 BO_ 213 BRAKE_POSITION: 8 XXX
 SG_ BRAKE_POSITION : 0|9@1+ (1,0) [0|1] "" XXX

BO_ 287 STEER_ANGLE_SENSOR: 5 XXX
 SG_ STEER_RACK_ANGLE : 0|16@1- (0.01,0) [-50|50] "deg" XXX
 SG_ STEER_TORQUE_MAG : 16|8@1+ (1,0) [0|255] "Nm" XXX

BO_ 289 NEW_MSG_121: 8 XXX

BO_ 482 NEW_MSG_1E2: 8 XXX
 SG_ STEER_ANGLE_2 : 24|16@1- (0.01,0) [0|65535] "" XXX

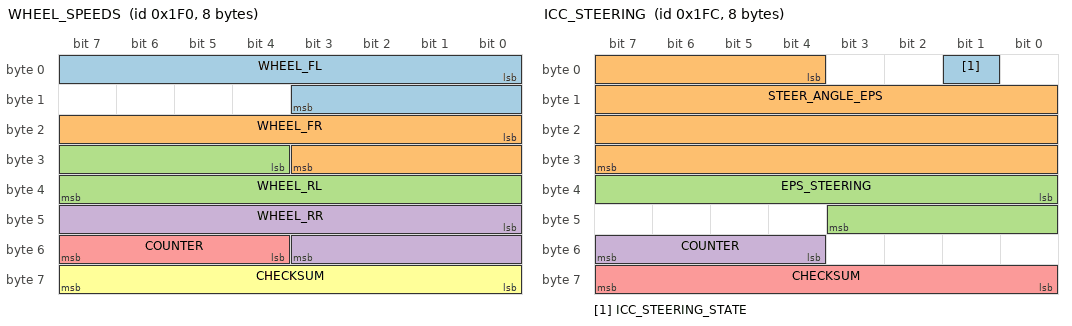
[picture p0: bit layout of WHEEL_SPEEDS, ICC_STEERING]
BO_ 496 WHEEL_SPEEDS: 8 XXX
 SG_ WHEEL_FL : 0|12@1+ (0.075,0) [0|4095] "" XXX
 SG_ WHEEL_FR : 16|12@1+ (0.075,0) [0|4095] "" XXX
 SG_ WHEEL_RL : 28|12@1+ (0.075,0) [0|31] "" XXX
 SG_ WHEEL_RR : 40|12@1+ (0.075,0) [0|8191] "" XXX
 SG_ COUNTER : 55|4@0+ (1,0) [0|15] "" XXX
 SG_ CHECKSUM : 56|8@1+ (1,0) [0|255] "" XXX

BO_ 508 ICC_STEERING: 8 XXX
 SG_ ICC_STEERING_STATE : 1|1@0+ (1,0) [0|1] "" XXX
 SG_ STEER_ANGLE_EPS : 4|28@1- (1,0) [-1000|1000] "" XXX
 SG_ EPS_STEERING : 32|12@1- (1,0) [-2048|2047] "" XXX
 SG_ COUNTER : 55|4@0+ (1,0) [0|15] "" XXX
 SG_ CHECKSUM : 63|8@0+ (1,0) [0|15] "" XXX

BO_ 537 BRAKE: 8 XXX
 SG_ BRAKE_PRESSED : 2|1@0+ (1,0) [0|1] "" XXX

BO_ 544 NEW_MSG_220: 8 XXX

BO_ 546 YAW_RATE: 8 XXX
 SG_ YAW_RATE : 0|11@1+ (1,-982) [0|2047] "" XXX

BO_ 547 NEW_MSG_223: 8 XXX

BO_ 578 NEW_MSG_242: 8 XXX
 SG_ GAS_PEDAL_2 : 30|7@0+ (1,0) [0|127] "" XXX
 SG_ BRAKE_STATE : 37|1@0+ (1,0) [0|1] "" XXX

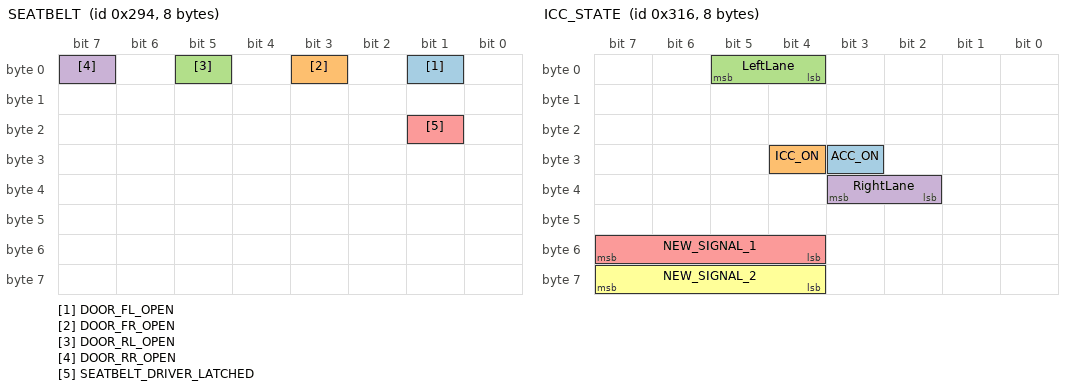
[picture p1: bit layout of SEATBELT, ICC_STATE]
BO_ 660 SEATBELT: 8 XXX
 SG_ DOOR_FL_OPEN : 1|1@0+ (1,0) [0|1] "" XXX
 SG_ DOOR_FR_OPEN : 3|1@0+ (1,0) [0|1] "" XXX
 SG_ DOOR_RL_OPEN : 5|1@0+ (1,0) [0|1] "" XXX
 SG_ DOOR_RR_OPEN : 7|1@0+ (1,0) [0|1] "" XXX
 SG_ SEATBELT_DRIVER_LATCHED : 17|1@0+ (1,0) [0|1] "" XXX

BO_ 661 NEW_MSG_295: 8 XXX

BO_ 790 ICC_STATE: 8 XXX
 SG_ ACC_ON : 27|1@0+ (1,0) [0|1] "" XXX
 SG_ ICC_ON : 28|1@0+ (1,0) [0|1] "" XXX
 SG_ LeftLane : 4|2@1+ (1,0) [0|3] "" XXX
 SG_ RightLane : 34|2@1+ (1,0) [0|3] "" XXX
 SG_ NEW_SIGNAL_1 : 55|4@0+ (1,0) [0|15] "" XXX
 SG_ NEW_SIGNAL_2 : 63|4@0+ (1,0) [0|15] "" XXX

BO_ 814 ICC_GAS_NOTSURE: 8 XXX
 SG_ GAS_NOTSURE : 7|16@0+ (1,0) [0|65535] "" XXX
 SG_ CHECKSUM : 51|12@0+ (1,0) [0|4095] "" XXX

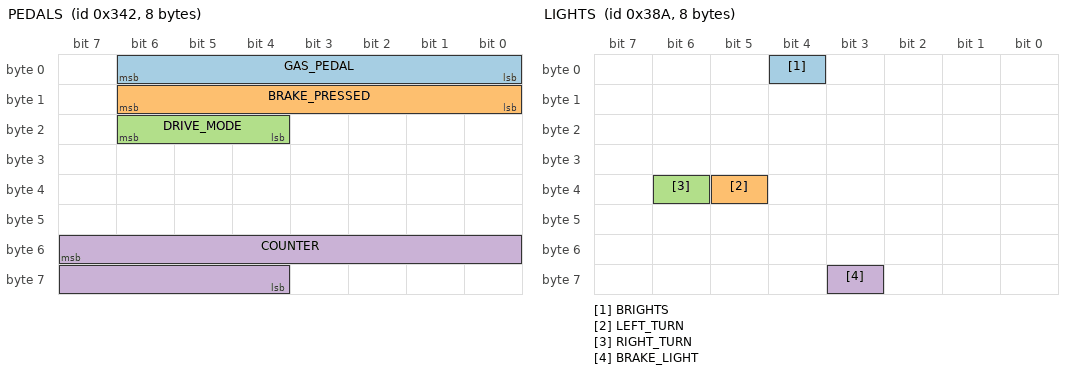
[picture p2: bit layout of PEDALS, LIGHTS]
BO_ 834 PEDALS: 8 XXX
 SG_ GAS_PEDAL : 6|7@0+ (1,0) [0|127] "" XXX
 SG_ BRAKE_PRESSED : 14|7@0+ (1,0) [0|1] "" XXX
 SG_ DRIVE_MODE : 22|3@0+ (1,0) [0|7] "" XXX
 SG_ COUNTER : 55|12@0+ (1,0) [0|4095] "" XXX

BO_ 854 NEW_MSG_356: 8 XXX

BO_ 860 GEAR_STATE: 8 XXX
 SG_ GEAR_STATE : 8|3@1+ (1,0) [0|7] "" XXX

BO_ 906 LIGHTS: 8 XXX
 SG_ BRIGHTS : 4|1@0+ (1,0) [0|1] "" XXX
 SG_ LEFT_TURN : 37|1@0+ (1,0) [0|1] "" XXX
 SG_ RIGHT_TURN : 38|1@0+ (1,0) [0|1] "" XXX
 SG_ BRAKE_LIGHT : 59|1@0+ (1,0) [0|1] "" XXX

BO_ 944 STEERING_WHEEL_BUTTONS: 8 XXX
 SG_ ACC_SPEED_BUTTON_MINUS : 3|1@1+ (1,0) [0|3] "" XXX
 SG_ ACC_SPEED_BUTTON_PLUS : 4|2@0+ (1,0) [0|3] "" XXX
 SG_ ACC_BUTTON : 6|1@0+ (1,0) [0|1] "" XXX
 SG_ ACC_DISTANCE_BUTTON_NOTSURE_MINUS : 15|1@0+ (1,0) [0|1] "" XXX
 SG_ ACC_DISTANCE_BUTTON_NOTSURE_PLUS : 16|1@0+ (1,0) [0|1] "" XXX

BO_ 1028 IGNITION: 8 XXX
 SG_ IGNITION_ON : 6|1@0+ (1,0) [0|1] "" XXX
 SG_ COUNTER_ignition : 60|4@1+ (1,0) [0|15] "" XXX

BO_ 1033 NEW_MSG_409: 8 XXX

BO_ 1040 xxxx: 8 XXX

BO_ 1058 MAYBE_RPM: 8 XXX

BO_ 1092 NEW_MSG_444: 8 XXX

BO_ 1093 maybe_ignition: 8 XXX

BO_ 1189 NEW_MSG_4A5: 8 XXX

BO_ 1193 DRIVING_MODE_BUTTON: 8 XXX
 SG_ DRIVING_MODE_BUTTON_PRESSED : 40|1@0+ (1,0) [0|1] "" XXX

CM_ BO_ 1193 "to be deleted";
VAL_ 834 DRIVE_MODE 0 "RESERVED" 1 "ECO" 2 "SPORT" 3 "SNOW" 4 "NORMAL" 5 "RESERVED" 6 "RESERVED" 7 "RESERVED";
VAL_ 860 GEAR_STATE 1 "P" 2 "R" 3 "N" 4 "D" 0 "UNKNOWN" 5 "UNKNOWN" 6 "UNKNOWN" 7 "UNKNOWN";
